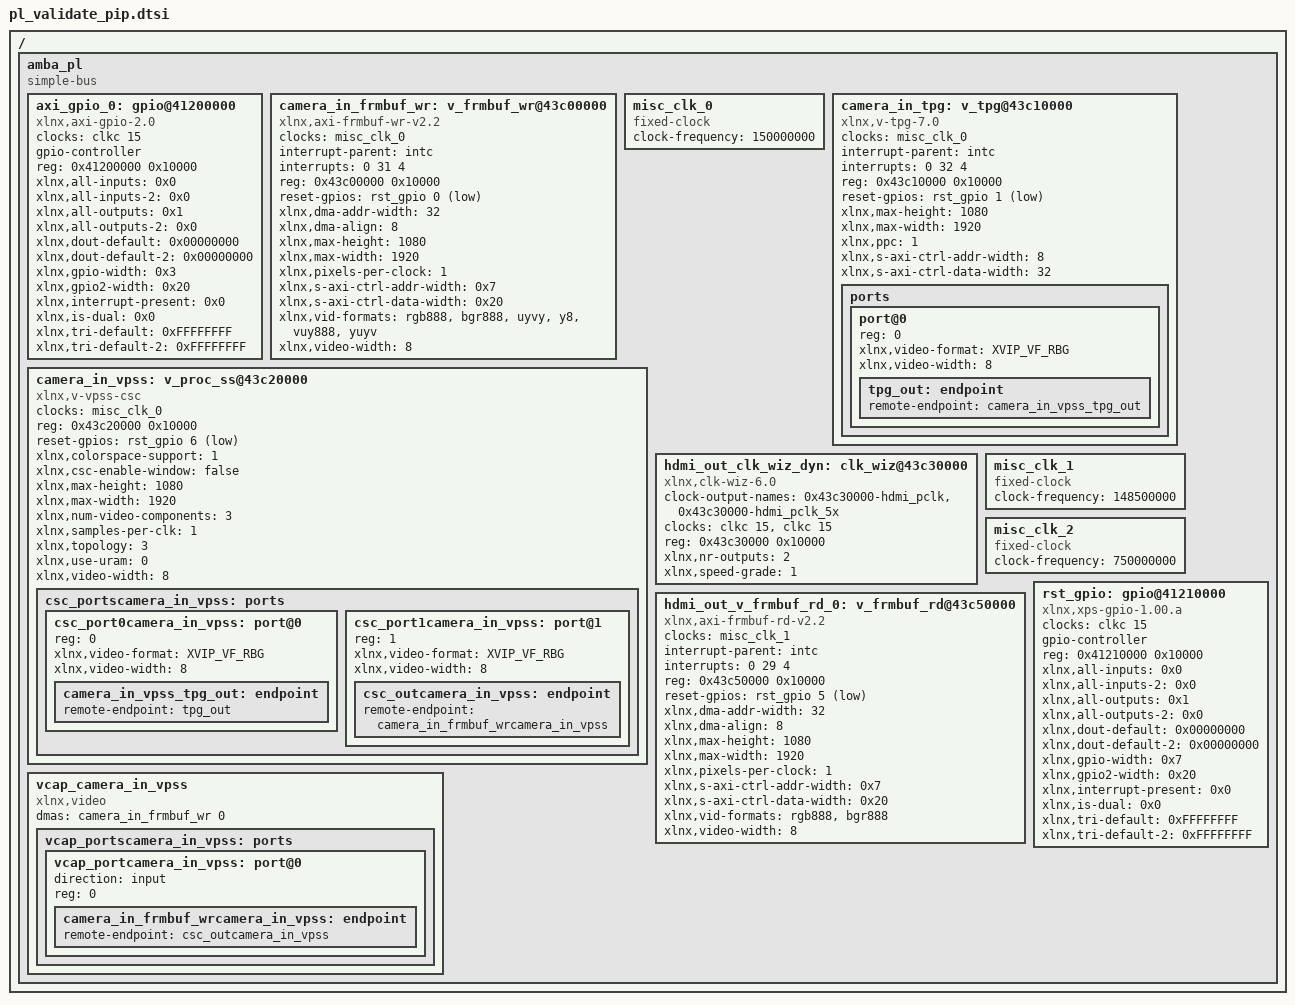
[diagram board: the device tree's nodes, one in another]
/*
 * CAUTION: This file is automatically generated by Xilinx.
 * Version: XSCT 
 * Today is: Wed Oct 29 11:52:34 2025
 */
#include <dt-bindings/media/xilinx-vip.h>
#include <dt-bindings/gpio/gpio.h>


/ {
	amba_pl: amba_pl {
		#address-cells = <1>;
		#size-cells = <1>;
		compatible = "simple-bus";
		ranges ;
		axi_gpio_0: gpio@41200000 {
			#gpio-cells = <2>;
			clock-names = "s_axi_aclk";
			clocks = <&clkc 15>;
			compatible = "xlnx,axi-gpio-2.0", "xlnx,xps-gpio-1.00.a";
			gpio-controller ;
			reg = <0x41200000 0x10000>;
			xlnx,all-inputs = <0x0>;
			xlnx,all-inputs-2 = <0x0>;
			xlnx,all-outputs = <0x1>;
			xlnx,all-outputs-2 = <0x0>;
			xlnx,dout-default = <0x00000000>;
			xlnx,dout-default-2 = <0x00000000>;
			xlnx,gpio-width = <0x3>;
			xlnx,gpio2-width = <0x20>;
			xlnx,interrupt-present = <0x0>;
			xlnx,is-dual = <0x0>;
			xlnx,tri-default = <0xFFFFFFFF>;
			xlnx,tri-default-2 = <0xFFFFFFFF>;
		};
		camera_in_frmbuf_wr: v_frmbuf_wr@43c00000 {
			#dma-cells = <1>;
			clock-names = "ap_clk";
			clocks = <&misc_clk_0>;
			compatible = "xlnx,axi-frmbuf-wr-v2.2";
			interrupt-names = "interrupt";
			interrupt-parent = <&intc>;
			interrupts = <0 31 4>;
			reg = <0x43c00000 0x10000>;
			reset-gpios = <&rst_gpio 0 1>;
			xlnx,dma-addr-width = <32>;
			xlnx,dma-align = <8>;
			xlnx,max-height = <1080>;
			xlnx,max-width = <1920>;
			xlnx,pixels-per-clock = <1>;
			xlnx,s-axi-ctrl-addr-width = <0x7>;
			xlnx,s-axi-ctrl-data-width = <0x20>;
			xlnx,vid-formats = "rgb888", "bgr888", "uyvy", "y8", "vuy888", "yuyv";
			xlnx,video-width = <8>;
		};
		misc_clk_0: misc_clk_0 {
			#clock-cells = <0>;
			clock-frequency = <150000000>;
			compatible = "fixed-clock";
		};
		camera_in_tpg: v_tpg@43c10000 {
			clock-names = "ap_clk";
			clocks = <&misc_clk_0>;
			compatible = "xlnx,v-tpg-7.0";
			interrupt-names = "interrupt";
			interrupt-parent = <&intc>;
			interrupts = <0 32 4>;
			reg = <0x43c10000 0x10000>;
			reset-gpios = <&rst_gpio 1 1>;
			xlnx,max-height = <1080>;
			xlnx,max-width = <1920>;
			xlnx,ppc = <1>;
			xlnx,s-axi-ctrl-addr-width = <8>;
			xlnx,s-axi-ctrl-data-width = <32>;
			ports {
				#address-cells = <1>;
				#size-cells = <0>;
				port@0 {
					reg = <0>;
					xlnx,video-format = <XVIP_VF_RBG>;
					xlnx,video-width = <8>;
					tpg_out: endpoint {
						remote-endpoint = <&camera_in_vpss_tpg_out>;
					};
				};
			};
		};
		camera_in_vpss: v_proc_ss@43c20000 {
			clock-names = "aclk";
			clocks = <&misc_clk_0>;
			compatible = "xlnx,v-vpss-csc";
			reg = <0x43c20000 0x10000>;
			reset-gpios = <&rst_gpio 6 1>;
			xlnx,colorspace-support = <1>;
			xlnx,csc-enable-window = "false";
			xlnx,max-height = <1080>;
			xlnx,max-width = <1920>;
			xlnx,num-video-components = <3>;
			xlnx,samples-per-clk = <1>;
			xlnx,topology = <3>;
			xlnx,use-uram = <0>;
			xlnx,video-width = <8>;
			csc_portscamera_in_vpss: ports {
				#address-cells = <1>;
				#size-cells = <0>;
				csc_port0camera_in_vpss: port@0 { 
					//port 0 must declare first, or it will cause kernel panic
					/* For xlnx,video-format user needs to fill as per their requirement */
					reg = <0>;
					xlnx,video-format = <XVIP_VF_RBG>;
					xlnx,video-width = <8>;
					camera_in_vpss_tpg_out: endpoint {
						remote-endpoint = <&tpg_out>;
					};
				};
				csc_port1camera_in_vpss: port@1 {
					/* For xlnx,video-format user needs to fill as per their requirement */
					reg = <1>;
					xlnx,video-format = <XVIP_VF_RBG>;
					xlnx,video-width = <8>;
					csc_outcamera_in_vpss: endpoint {
						remote-endpoint = <&camera_in_frmbuf_wrcamera_in_vpss>;
					};
				};
			};
		};
		hdmi_out_clk_wiz_dyn: clk_wiz@43c30000 {
			#clock-cells = <1>;
			clock-names = "s_axi_aclk", "clk_in1";
			clock-output-names = "0x43c30000-hdmi_pclk", "0x43c30000-hdmi_pclk_5x";
			clocks = <&clkc 15>, <&clkc 15>;
			compatible = "xlnx,clk-wiz-6.0", "xlnx,clocking-wizard";
			reg = <0x43c30000 0x10000>;
			xlnx,nr-outputs = <2>;
			xlnx,speed-grade = <1>;
		};
		// hdmi_out_hdmi_vtc: v_tc@43c40000 {
		// 	clock-names = "clk", "s_axi_aclk";
		// 	clocks = <&misc_clk_1>, <&clkc 15>;
		// 	compatible = "xlnx,v-tc-6.2", "xlnx,v-tc-6.1";
		// 	interrupt-names = "irq";
		// 	interrupt-parent = <&intc>;
		// 	interrupts = <0 30 4>;
		// 	reg = <0x43c40000 0x10000>;
		// 	xlnx,generator ;
		// };
		misc_clk_1: misc_clk_1 {
			#clock-cells = <0>;
			clock-frequency = <148500000>;
			compatible = "fixed-clock";
		};
		misc_clk_2: misc_clk_2 {
			#clock-cells = <0>;
			clock-frequency = <750000000>;
			compatible = "fixed-clock";
		};
		hdmi_out_v_frmbuf_rd_0: v_frmbuf_rd@43c50000 {
			#dma-cells = <1>;
			clock-names = "ap_clk";
			clocks = <&misc_clk_1>;
			compatible = "xlnx,axi-frmbuf-rd-v2.2";
			interrupt-names = "interrupt";
			interrupt-parent = <&intc>;
			interrupts = <0 29 4>;
			reg = <0x43c50000 0x10000>;
			reset-gpios = <&rst_gpio 5 1>;
			xlnx,dma-addr-width = <32>;
			xlnx,dma-align = <8>;
			xlnx,max-height = <1080>;
			xlnx,max-width = <1920>;
			xlnx,pixels-per-clock = <1>;
			xlnx,s-axi-ctrl-addr-width = <0x7>;
			xlnx,s-axi-ctrl-data-width = <0x20>;
			xlnx,vid-formats = "rgb888", "bgr888";
			xlnx,video-width = <8>;
		};
		rst_gpio: gpio@41210000 {
			#gpio-cells = <2>;
			clock-names = "s_axi_aclk";
			clocks = <&clkc 15>;
			compatible = "xlnx,xps-gpio-1.00.a";
			gpio-controller ;
			reg = <0x41210000 0x10000>;
			xlnx,all-inputs = <0x0>;
			xlnx,all-inputs-2 = <0x0>;
			xlnx,all-outputs = <0x1>;
			xlnx,all-outputs-2 = <0x0>;
			xlnx,dout-default = <0x00000000>;
			xlnx,dout-default-2 = <0x00000000>;
			xlnx,gpio-width = <0x7>;
			xlnx,gpio2-width = <0x20>;
			xlnx,interrupt-present = <0x0>;
			xlnx,is-dual = <0x0>;
			xlnx,tri-default = <0xFFFFFFFF>;
			xlnx,tri-default-2 = <0xFFFFFFFF>;
		};
		vcap_camera_in_vpss {
			compatible = "xlnx,video";
			dma-names = "port0";
			dmas = <&camera_in_frmbuf_wr 0>;
			vcap_portscamera_in_vpss: ports {
				#address-cells = <1>;
				#size-cells = <0>;
				vcap_portcamera_in_vpss: port@0 {
					direction = "input";
					reg = <0>;
					camera_in_frmbuf_wrcamera_in_vpss: endpoint {
						remote-endpoint = <&csc_outcamera_in_vpss>;
					};
				};
			};
		};
	};
};
